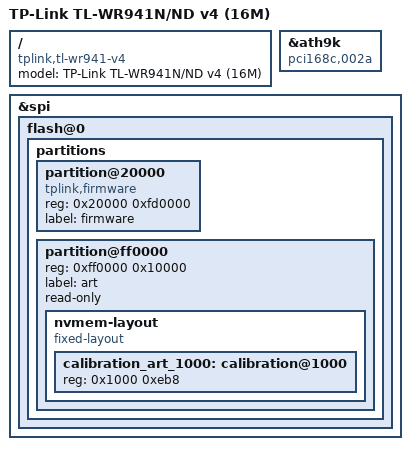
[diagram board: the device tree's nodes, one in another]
// SPDX-License-Identifier: GPL-2.0-or-later OR MIT
//
// TL-WR941ND v4 with a 16 MB flash chip: the stock board, with a partition
// table that spans the whole chip and keeps art in its last 64 KiB. The stock
// compatible stays, so board.d sets up the switch, LAN and WAN as on the v4.

#include "ar7240_tplink_tl-wr.dtsi"

/ {
    model = "TP-Link TL-WR941N/ND v4 (16M)";
    compatible = "tplink,tl-wr941-v4", "qca,ar7240";
};

// The AR9280 binds by PCI id and reads its calibration through the nvmem cell
// in the art partition below.
&ath9k {
    compatible = "pci168c,002a";
};

&spi {
    flash@0 {
        partitions {
            /delete-node/ partition@20000;
            /delete-node/ partition@3f0000;

            partition@20000 {
                compatible = "tplink,firmware";
                reg = <0x20000 0xfd0000>;
                label = "firmware";
            };

            partition@ff0000 {
                reg = <0xff0000 0x10000>;
                label = "art";
                read-only;

                // Same offset inside art as on the stock layout: the art
                // contents move to the new address unchanged.
                nvmem-layout {
                    compatible = "fixed-layout";
                    #address-cells = <1>;
                    #size-cells = <1>;

                    calibration_art_1000: calibration@1000 {
                        reg = <0x1000 0xeb8>;
                    };
                };
            };
        };
    };
};
